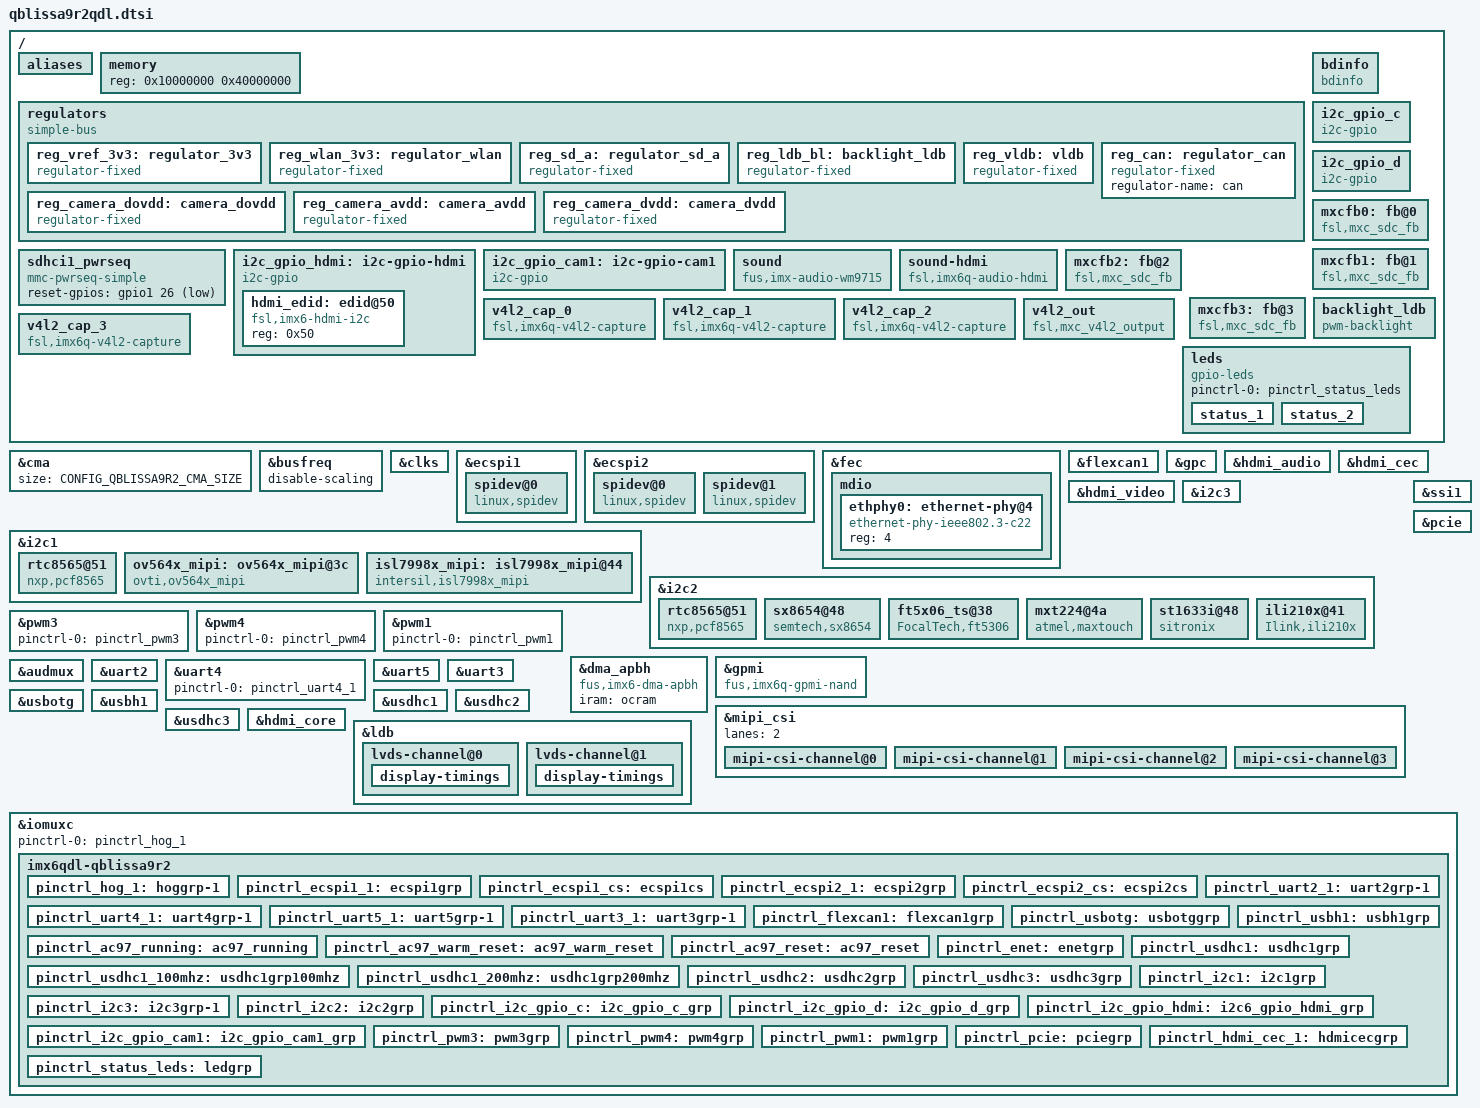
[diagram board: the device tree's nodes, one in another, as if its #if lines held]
/*
 * Copyright 2016-2017 F&S Elektronik Systeme GmbH
 *
 * This program is free software; you can redistribute it and/or modify
 * it under the terms of the GNU General Public License version 2 as
 * published by the Free Software Foundation.
 */

#include <dt-bindings/pwm/pwm.h>

/* Do we have HDMI? */
#if ((CONFIG_QBLISSA9R2_MXCFB0 == DISPLAY_HDMI) \
    || (CONFIG_QBLISSA9R2_MXCFB1 == DISPLAY_HDMI) \
    || (CONFIG_QBLISSA9R2_MXCFB2 == DISPLAY_HDMI) \
    || (CONFIG_QBLISSA9R2_MXCFB3 == DISPLAY_HDMI))
#define CONFIG_QBLISSA9R2_HDMI
#define CONFIG_QBLISSA9R2_HDMI_AUDIO
#define CONFIG_QBLISSA9R2_HDMI_CEC
#if ((CONFIG_QBLISSA9R2_MXCFB0 == DISPLAY_HDMI) \
    || (CONFIG_QBLISSA9R2_MXCFB1 == DISPLAY_HDMI))
#define __HDMI_ON_0_OR_1__	1
#define __HDMI_ON_2_OR_3__	0
#else
#define __HDMI_ON_0_OR_1__	0
#define __HDMI_ON_2_OR_3__	1
#endif
#endif

/* Do we have LVDS0? */
#if ((CONFIG_QBLISSA9R2_MXCFB0 == DISPLAY_LVDS0) \
    || (CONFIG_QBLISSA9R2_MXCFB1 == DISPLAY_LVDS0) \
    || (CONFIG_QBLISSA9R2_MXCFB2 == DISPLAY_LVDS0) \
    || (CONFIG_QBLISSA9R2_MXCFB3 == DISPLAY_LVDS0))
#define CONFIG_QBLISSA9R2_LVDS0
#if ((CONFIG_QBLISSA9R2_MXCFB0 == DISPLAY_LVDS0) \
    || (CONFIG_QBLISSA9R2_MXCFB1 == DISPLAY_LVDS0))
#define __LVDS0_ON_0_OR_1__	1
#define __LVDS0_ON_2_OR_3__	0
#else
#define __LVDS0_ON_0_OR_1__	0
#define __LVDS0_ON_2_OR_3__	1
#endif
#endif

/* Do we have LVDS1? */
#if ((CONFIG_QBLISSA9R2_MXCFB0 == DISPLAY_LVDS1) \
    || (CONFIG_QBLISSA9R2_MXCFB1 == DISPLAY_LVDS1) \
    || (CONFIG_QBLISSA9R2_MXCFB2 == DISPLAY_LVDS1) \
    || (CONFIG_QBLISSA9R2_MXCFB3 == DISPLAY_LVDS1))
#define CONFIG_QBLISSA9R2_LVDS1
#if ((CONFIG_QBLISSA9R2_MXCFB0 == DISPLAY_LVDS1) \
    || (CONFIG_QBLISSA9R2_MXCFB1 == DISPLAY_LVDS1))
#define __LVDS1_ON_0_OR_1__	1
#define __LVDS1_ON_2_OR_3__	0
#else
#define __LVDS1_ON_0_OR_1__	0
#define __LVDS1_ON_2_OR_3__	1
#endif
#endif

/* Check which LVDS will be the primary display */
#if (CONFIG_QBLISSA9R2_MXCFB0 == DISPLAY_LVDS0)
#define __LVDS0_PRIMARY__
#elif (CONFIG_QBLISSA9R2_MXCFB0 == DISPLAY_LVDS1)
#define __LVDS1_PRIMARY__
#elif (CONFIG_QBLISSA9R2_MXCFB1 == DISPLAY_LVDS0)
#define __LVDS0_PRIMARY__
#elif (CONFIG_QBLISSA9R2_MXCFB1 == DISPLAY_LVDS1)
#define __LVDS1_PRIMARY__
#elif (CONFIG_QBLISSA9R2_MXCFB2 == DISPLAY_LVDS0)
#define __LVDS0_PRIMARY__
#elif (CONFIG_QBLISSA9R2_MXCFB2 == DISPLAY_LVDS1)
#define __LVDS1_PRIMARY__
#elif (CONFIG_QBLISSA9R2_MXCFB3 == DISPLAY_LVDS0)
#define __LVDS0_PRIMARY__
#elif (CONFIG_QBLISSA9R2_MXCFB3 == DISPLAY_LVDS1)
#define __LVDS1_PRIMARY__
#endif

/* Check for invalid CONFIG combinations */

/* If SD_A is not active, also CD and WP may not be used */
#ifndef CONFIG_QBLISSA9R2_SD_A
#undef CONFIG_QBLISSA9R2_SD_A_CD
#undef CONFIG_QBLISSA9R2_SD_A_WP
#endif

/ {
	aliases {
		mxcfb0 = &mxcfb0;
		mxcfb1 = &mxcfb1;
		mxcfb2 = &mxcfb2;
		mxcfb3 = &mxcfb3;
#ifdef CONFIG_QBLISSA9R2_I2C_C
		i2c3 = &i2c_gpio_c;
#endif
#ifdef CONFIG_QBLISSA9R2_I2C_D
		i2c4 = &i2c_gpio_d;
#endif
#ifdef CONFIG_QBLISSA9R2_HDMI
		i2c5 = &i2c_gpio_hdmi;
#endif
#ifdef CONFIG_QBLISSA9R2_SERIAL_CAMERA
		i2c6 = &i2c_gpio_cam1;
#endif
	};

	memory {
		reg = <0x10000000 0x40000000>;
	};

	regulators {
		compatible = "simple-bus";

		reg_vref_3v3: regulator_3v3 {
			compatible = "regulator-fixed";
			regulator-name = "vref-3V3";
			regulator-min-microvolt = <3300000>;
			regulator-max-microvolt = <3300000>;
			regulator-always-on;
		};

#ifdef CONFIG_QBLISSA9R2_WLAN
		reg_wlan_3v3: regulator_wlan {
			compatible = "regulator-fixed";
			regulator-name = "vmmc-wlan-3v3";
			regulator-min-microvolt = <3300000>;
			regulator-max-microvolt = <3300000>;
//###			gpio = <&gpio1 26 GPIO_ACTIVE_HIGH>;
//###			enable-active-high;
			regulator-always-on;
		};
#endif

#ifdef CONFIG_QBLISSA9R2_SD_A
		reg_sd_a: regulator_sd_a {
			compatible = "regulator-fixed";
			regulator-name = "SD_A";
			regulator-min-microvolt = <3300000>;
			regulator-max-microvolt = <3300000>;
			gpio = <&gpio3 14 0>;
		};
#endif

		/* USB_OTG_PWR handled by USB controller, no regulator needed */
#if 0 //###
		reg_usb_otg_vbus: usb_otg_vbus {
			compatible = "regulator-fixed";
			regulator-name = "usb_otg_vbus";
			regulator-min-microvolt = <5000000>;
			regulator-max-microvolt = <5000000>;
			gpio = <&gpio3 22 GPIO_ACTIVE_LOW>;
		};
#endif //###

		/* USB_H1_PWR is always on, no regulator needed */
#if 0 //###
		reg_usb_h1_vbus: usb_h1_vbus {
			compatible = "regulator-fixed";
			regulator-name = "usb_h1_vbus";
			regulator-min-microvolt = <5000000>;
			regulator-max-microvolt = <5000000>;
			/* No way to switch USB1_H1_VBUS power */
			regulator-always-on;
		};
#endif //###

		/* LVDS backlight */
		reg_ldb_bl: backlight_ldb {
			compatible = "regulator-fixed";
			regulator-name = "ldb-bl";
			gpio = <&gpio2 8 GPIO_ACTIVE_HIGH>;
			regulator-min-microvolt = <3300000>;
			regulator-max-microvolt = <3300000>;
			enable-active-high;
		};

		/* LVDS logic supply power */
		reg_vldb: vldb {
			compatible = "regulator-fixed";
			regulator-name = "VLDB";
			gpio = <&gpio2 11 GPIO_ACTIVE_HIGH>;
			regulator-min-microvolt = <3300000>;
			regulator-max-microvolt = <3300000>;
			enable-active-high;
		};

		/* CAN */
		reg_can: regulator_can {
			compatible = "regulator-fixed";
			regulator-name = "can";
		};

#ifdef CONFIG_QBLISSA9R2_SERIAL_CAMERA
		reg_camera_dovdd: camera_dovdd {
			compatible = "regulator-fixed";
			regulator-name = "DOVDD-supply";
			regulator-min-microvolt = <1800000>;
			regulator-max-microvolt = <1800000>;
		};

		reg_camera_avdd: camera_avdd {
			compatible = "regulator-fixed";
			regulator-name = "VAVDD-supply";
			regulator-min-microvolt = <2800000>;
			regulator-max-microvolt = <2800000>;
		};

		reg_camera_dvdd: camera_dvdd {
			compatible = "regulator-fixed";
			regulator-name = "DVDD-supply";
			regulator-min-microvolt = <1500000>;
			regulator-max-microvolt = <1500000>;
		};
#endif /* CONFIG_QBLISSA9R2_SERIAL_CAMERA */
	};

	/* F&S board information */
	bdinfo: bdinfo {
		compatible = "bdinfo";
		board_name = "qblissa9r2";
		ecc_strength = "8";
	};

#if 1 //###
	sdhci1_pwrseq: sdhci1_pwrseq {
		compatible = "mmc-pwrseq-simple";
		reset-gpios = <&gpio1 26 GPIO_ACTIVE_LOW>;
	};
#endif //###

#ifdef CONFIG_QBLISSA9R2_I2C_C
	i2c_gpio_c: i2c_gpio_c {
		compatible = "i2c-gpio";
		gpios = <&gpio2 15 GPIO_ACTIVE_HIGH /* sda */
			 &gpio2 14 GPIO_ACTIVE_HIGH /* scl */
			>;
		pinctrl-names = "default";
		pinctrl-0 = <&pinctrl_i2c_gpio_c>;
//		i2c-gpio,sda-open-drain;
//		i2c-gpio,scl-open-drain;
		i2c-gpio,delay-us = <2>;        /* ~100 kHz */
		#address-cells = <1>;
		#size-cells = <0>;
	};
#endif

#ifdef CONFIG_QBLISSA9R2_I2C_D
	i2c_gpio_d: i2c_gpio_d {
		compatible = "i2c-gpio";
		gpios = <&gpio5 8 GPIO_ACTIVE_HIGH /* sda */
			 &gpio5 9 GPIO_ACTIVE_HIGH /* scl */
			>;
		pinctrl-names = "default";
		pinctrl-0 = <&pinctrl_i2c_gpio_d>;
		i2c-gpio,delay-us = <2>;        /* ~100 kHz */
		#address-cells = <1>;
		#size-cells = <0>;
	};
#endif

#ifdef CONFIG_QBLISSA9R2_HDMI
	i2c_gpio_hdmi: i2c-gpio-hdmi {
		compatible = "i2c-gpio";
		gpios = <&gpio5 10 GPIO_ACTIVE_HIGH /* sda */
			 &gpio5 11 GPIO_ACTIVE_HIGH /* scl */
			>;
		pinctrl-names = "default";
		pinctrl-0 = <&pinctrl_i2c_gpio_hdmi>;
		//i2c-gpio,sda-open-drain;
		//i2c-gpio,scl-open-drain;
		i2c-gpio,delay-us = <2>;        /* ~100 kHz */
		#address-cells = <1>;
		#size-cells = <0>;
	};
#endif

#ifdef CONFIG_QBLISSA9R2_SERIAL_CAMERA
	i2c_gpio_cam1: i2c-gpio-cam1 {
		compatible = "i2c-gpio";
		gpios = <&gpio6 0 GPIO_ACTIVE_HIGH /* sda */
			 &gpio6 1 GPIO_ACTIVE_HIGH /* scl */
			>;
		pinctrl-names = "default";
		pinctrl-0 = <&pinctrl_i2c_gpio_cam1>;
		i2c-gpio,delay-us = <2>;        /* ~100 kHz */
		#address-cells = <1>;
		#size-cells = <0>;
	};
#endif

#ifdef CONFIG_QBLISSA9R2_WM9715_AUDIO
	sound {
		compatible = "fus,imx-audio-wm9715";
		fus,model = "F&S Audio WM9715";
		audio-cpu = <&ssi1>;
		clocks = <&clks IMX6QDL_CLK_DUMMY>;
		mux-int-port = <1>;  /* SSI1=1, SSI2=2, SSI3=7 */
		mux-ext-port = <4>;
	};
#endif

#ifdef CONFIG_QBLISSA9R2_HDMI_AUDIO
	sound-hdmi {
		compatible = "fsl,imx6q-audio-hdmi", "fsl,imx-audio-hdmi";
		model = "imx-audio-hdmi";
		hdmi-controller = <&hdmi_audio>;
	};
#endif

	mxcfb0: fb@0 {
		compatible = "fsl,mxc_sdc_fb";
		late_init = <0>;
#if (CONFIG_QBLISSA9R2_MXCFB0 == DISPLAY_HDMI)
		disp_dev = "hdmi";
		default_bpp = <CONFIG_QBLISSA9R2_HDMI_BPP>;
		interface_pix_fmt = CONFIG_QBLISSA9R2_HDMI_PIX_FMT;
		int_clk = <0>;
		mode_str = CONFIG_QBLISSA9R2_HDMI_MODE_STR;
#elif (CONFIG_QBLISSA9R2_MXCFB0 == DISPLAY_LVDS0)
		disp_dev = "ldb";
		default_bpp = <CONFIG_QBLISSA9R2_LVDS0_BPP>;
		interface_pix_fmt = CONFIG_QBLISSA9R2_LVDS0_PIX_FMT;
		int_clk = <1>;
#elif (CONFIG_QBLISSA9R2_MXCFB0 == DISPLAY_LVDS1)
		disp_dev = "ldb";
		default_bpp = <CONFIG_QBLISSA9R2_LVDS1_BPP>;
		interface_pix_fmt = CONFIG_QBLISSA9R2_LVDS1_PIX_FMT;
		int_clk = <1>;
#else
		status = "disabled";
#endif
	};

	mxcfb1: fb@1 {
		compatible = "fsl,mxc_sdc_fb";
		late_init = <0>;
#if (CONFIG_QBLISSA9R2_MXCFB1 == DISPLAY_HDMI)
		disp_dev = "hdmi";
		default_bpp = <CONFIG_QBLISSA9R2_HDMI_BPP>;
		interface_pix_fmt = CONFIG_QBLISSA9R2_HDMI_PIX_FMT;
		int_clk = <0>;
		mode_str = CONFIG_QBLISSA9R2_HDMI_MODE_STR;
#elif (CONFIG_QBLISSA9R2_MXCFB1 == DISPLAY_LVDS0)
		disp_dev = "ldb";
		default_bpp = <CONFIG_QBLISSA9R2_LVDS0_BPP>;
		interface_pix_fmt = CONFIG_QBLISSA9R2_LVDS0_PIX_FMT;
		int_clk = <1>;
#elif (CONFIG_QBLISSA9R2_MXCFB1 == DISPLAY_LVDS1)
		disp_dev = "ldb";
		default_bpp = <CONFIG_QBLISSA9R2_LVDS1_BPP>;
		interface_pix_fmt = CONFIG_QBLISSA9R2_LVDS1_PIX_FMT;
		int_clk = <1>;
#else
		status = "disabled";
#endif
	};

	mxcfb2: fb@2 {
		compatible = "fsl,mxc_sdc_fb";
		late_init = <0>;
#if (CONFIG_QBLISSA9R2_MXCFB2 == DISPLAY_HDMI)
		disp_dev = "hdmi";
		default_bpp = <CONFIG_QBLISSA9R2_HDMI_BPP>;
		interface_pix_fmt = CONFIG_QBLISSA9R2_HDMI_PIX_FMT;
		int_clk = <0>;
		mode_str = CONFIG_QBLISSA9R2_HDMI_MODE_STR;
#elif (CONFIG_QBLISSA9R2_MXCFB2 == DISPLAY_LVDS0)
		disp_dev = "ldb";
		default_bpp = <CONFIG_QBLISSA9R2_LVDS0_BPP>;
		interface_pix_fmt = CONFIG_QBLISSA9R2_LVDS0_PIX_FMT;
		int_clk = <1>;
#elif (CONFIG_QBLISSA9R2_MXCFB2 == DISPLAY_LVDS1)
		disp_dev = "ldb";
		default_bpp = <CONFIG_QBLISSA9R2_LVDS1_BPP>;
		interface_pix_fmt = CONFIG_QBLISSA9R2_LVDS1_PIX_FMT;
		int_clk = <1>;
#else
		status = "disabled";
#endif
	};

	mxcfb3: fb@3 {
		compatible = "fsl,mxc_sdc_fb";
		late_init = <0>;
#if (CONFIG_QBLISSA9R2_MXCFB3 == DISPLAY_HDMI)
		disp_dev = "hdmi";
		default_bpp = <CONFIG_QBLISSA9R2_HDMI_BPP>;
		interface_pix_fmt = CONFIG_QBLISSA9R2_HDMI_PIX_FMT;
		int_clk = <0>;
		mode_str = CONFIG_QBLISSA9R2_HDMI_MODE_STR;
#elif (CONFIG_QBLISSA9R2_MXCFB3 == DISPLAY_LVDS0)
		disp_dev = "ldb";
		default_bpp = <CONFIG_QBLISSA9R2_LVDS0_BPP>;
		interface_pix_fmt = CONFIG_QBLISSA9R2_LVDS0_PIX_FMT;
		int_clk = <1>;
#elif (CONFIG_QBLISSA9R2_MXCFB3 == DISPLAY_LVDS1)
		disp_dev = "ldb";
		default_bpp = <CONFIG_QBLISSA9R2_LVDS1_BPP>;
		interface_pix_fmt = CONFIG_QBLISSA9R2_LVDS1_PIX_FMT;
		int_clk = <1>;
#else
		status = "disabled";
#endif
	};

#if (defined(CONFIG_QBLISSA9R2_LVDS0) || defined(CONFIG_QBLISSA9R2_LVDS1))
	/* LVDS backlight PWM (PWM3) */
	backlight_ldb {
		compatible = "pwm-backlight";
		pwms = <&pwm3 0 5000000>;
		power-supply = <&reg_ldb_bl>;
		brightness-levels = <0 1 5 10 18 28 41 56
				     73 92 113 137 163 192 222 255>;
		default-brightness-level = <14>;
		fb-names = "mxs-lcdif1";
	};
#endif

	/* Serial MIPI camera interface */
#ifdef CONFIG_QBLISSA9R2_SERIAL_CAMERA
	/* First capture device for first MIPI channel */
	v4l2_cap_0 {
		compatible = "fsl,imx6q-v4l2-capture";
		ipu_id = <0>;
		csi_id = <0>;
		mclk_source = <0>;
		status = "okay";
	};

	/* Second capture device, for second MIPI channel */
	v4l2_cap_1 {
		compatible = "fsl,imx6q-v4l2-capture";
		ipu_id = <0>;
		csi_id = <1>;
		mclk_source = <0>;
		status = "okay";
	};

#ifndef CONFIG_QBLISSA9R2_USE_ONE_IPU
	/* Third capture device, for third MIPI channel */
	v4l2_cap_2 {
		compatible = "fsl,imx6q-v4l2-capture";
		ipu_id = <1>;
		csi_id = <0>;
		mclk_source = <0>;
		status = "okay";
	};

	/* Fourth capture device, for fourth MIPI channel */
	v4l2_cap_3 {
		compatible = "fsl,imx6q-v4l2-capture";
		ipu_id = <1>;
		csi_id = <1>;
		mclk_source = <0>;
		status = "okay";
	};
#endif

	v4l2_out {
		compatible = "fsl,mxc_v4l2_output";
		status = "okay";
	};
#endif

	leds {
		compatible = "gpio-leds";
		pinctrl-names = "default";
		pinctrl-0 = <&pinctrl_status_leds>;

		status_1 {
			label = "Status1";
			gpios = <&gpio7 13 GPIO_ACTIVE_HIGH>;
			default-state = "keep";
		};

		status_2 {
			label = "Status2";
			gpios = <&gpio7 12 GPIO_ACTIVE_HIGH>;
			default-state = "keep";
		};
	};
};

/* RAM size for Continuous Memory Allocator; if not defined, use 320 MB */
#ifndef CONFIG_QBLISSA9R2_CMA_SIZE
#define CONFIG_QBLISSA9R2_CMA_SIZE 0x14000000
#endif
&cma {
	size = <CONFIG_QBLISSA9R2_CMA_SIZE>;
};

&busfreq {
	/* Disable bus frequency scaling, because reducing bus frequency to
	   24 MHz does not work with all types of DDR3 RAM */
	disable-scaling;
};

&clks {
	assigned-clocks = <&clks IMX6QDL_CLK_PLL4_AUDIO_DIV>,
			  <&clks IMX6QDL_CLK_SSI1_SEL>,
			  <&clks IMX6QDL_CLK_SSI1>;
	assigned-clock-parents = <0>,
				 <&clks IMX6QDL_CLK_PLL4_AUDIO_DIV>;
	/*
	 * The Audio-PLL (PLL4) must have at least 650MHz. The PLL post divider
	 * can divide by 1, 2 and 4, which means the lowest possible frequency
	 * is 162.5 MHz. Use 196.608 MHz, which is a multiple of 24.576 MHz.
	 * This is in turn a multiple of the commonly used audio bit rates.
	 */
	assigned-clock-rates = <196608000>, <196608000>, <24576000>;
};

#ifdef CONFIG_QBLISSA9R2_SPI_FLASH
&ecspi1 {
	fsl,spi-num-chipselects = <1>;
	cs-gpios = <&gpio2 30 GPIO_ACTIVE_HIGH>;
	pinctrl-names = "default";
	pinctrl-0 = <&pinctrl_ecspi1_1 &pinctrl_ecspi1_cs>;
	status = "okay";

	spidev@0 {
		#address-cells = <1>;
		#size-cells = <1>;
		compatible = "linux,spidev";
		spi-max-frequency = <20000000>;
		reg = <0>;
	};
};
#endif /* CONFIG_QBLISSA9R2_SPI_FLASH */

#ifdef CONFIG_QBLISSA9R2_SPI_A
/* SPI_A (2x CS) */
&ecspi2 {
	fsl,spi-num-chipselects = <2>;
	cs-gpios = <&gpio2 26 0>, <&gpio2 27 0>;
	pinctrl-names = "default";
	pinctrl-0 = <&pinctrl_ecspi2_1 &pinctrl_ecspi2_cs>;
	status = "okay";

	spidev@0 {
		#address-cells = <1>;
		#size-cells = <1>;
		compatible = "linux,spidev";
		spi-max-frequency = <20000000>;
		reg = <0>;
	};

	spidev@1 {
		#address-cells = <1>;
		#size-cells = <1>;
		compatible = "linux,spidev";
		spi-max-frequency = <20000000>;
		reg = <1>;
	};
};
#endif /* CONFIG_QBLISSA9R2_SPI_A */

&fec {
	pinctrl-names = "default";
	pinctrl-0 = <&pinctrl_enet>;
	phy-mode = "rgmii-id";
	phy-handle = <&ethphy0>;
	phy-supply = <&reg_vref_3v3>;
	status = "okay";

	mdio {
		#address-cells = <1>;
		#size-cells = <0>;

		ethphy0: ethernet-phy@4 {
			compatible = "ethernet-phy-ieee802.3-c22";
			reg = <4>;
			/* Set the maximum link speed if required */
			//max-speed = <100>;
		};
	};
};

/* CAN_A implemented by FLEXCAN1 */
&flexcan1 {
	pinctrl-names = "default";
	pinctrl-0 = <&pinctrl_flexcan1>;
	xceiver-supply = <&reg_can>;
	status = "okay";
};

&gpc {
	fsl,cpu_pupscr_sw2iso = <0xf>;
	fsl,cpu_pupscr_sw = <0xf>;
	fsl,cpu_pdnscr_iso2sw = <0x1>;
	fsl,cpu_pdnscr_iso = <0x1>;
	fsl,ldo-bypass = <0>; /* use ldo-bypass, u-boot will check it and configure */
	fsl,wdog-reset = <1>; /* watchdog select of reset source */
};

#ifdef CONFIG_QBLISSA9R2_HDMI_AUDIO
&hdmi_audio {
	status = "okay";
};
#endif

#ifdef CONFIG_QBLISSA9R2_HDMI_CEC
&hdmi_cec {
//###	pinctrl-names = "default";
//###	pinctrl-0 = <&pinctrl_hdmi_cec_1>;
	status = "okay";
};
#endif

#ifdef CONFIG_QBLISSA9R2_HDMI
&hdmi_video {
	fsl,phy_reg_vlev = <0x0294>;
	fsl,phy_reg_cksymtx = <0x800d>;
	hpd-active-low;
	force-dvi-mode;
	status = "okay";
};
#endif

/* I2C1 is used internally (RTC, EEPROM) and for cameras, always active */
&i2c1{
	clock-frequency = <100000>;
	pinctrl-names = "default";
	pinctrl-0 = <&pinctrl_i2c1>;
	status = "okay";

#if (CONFIG_QBLISSA9R2_BOARD_REVISION < 110)
	rtc8565@51 {
		compatible = "nxp,pcf8565", "nxp,pcf8563";
		reg = <0x51>;
		interrupt-parent = <&gpio1>;
		interrupts = <28 IRQ_TYPE_EDGE_FALLING>;
	};
#endif

#ifdef CONFIG_QBLISSA9R2_SERIAL_CAMERA
#ifdef CONFIG_QBLISSA9R2_MIPI_CAMERA_OV564X
	ov564x_mipi: ov564x_mipi@3c {
		compatible = "ovti,ov564x_mipi";
		reg = <0x3c>;
		clocks = <&clks 201>;
		clock-names = "csi_mclk";
		DOVDD-supply = <&reg_camera_dovdd>;
		AVDD-supply = <&reg_camera_avdd>;
		DVDD-supply = <&reg_camera_dvdd>;
		en-gpios = <&gpio5 24 GPIO_ACTIVE_LOW>;
		rst-gpios = <&gpio5 23 GPIO_ACTIVE_LOW>;
		csi_id = <0>;
		mclk = <24000000>;
		mclk_source = <0>;
	};
#endif
#ifdef CONFIG_QBLISSA9R2_MIPI_CAMERA_ISL7998X
	isl7998x_mipi: isl7998x_mipi@44 {
		compatible = "intersil,isl7998x_mipi";
		reg = <0x44>;
		clocks = <&clks IMX6QDL_CLK_CKO2>;
		clock-names = "csi_mclk";
		mclk = <27000000>;
	};
#endif
#endif
};

#ifdef CONFIG_QBLISSA9R2_I2C_A
/* I2C_A is implemented via I2C3 */
&i2c3 {
	clock-frequency = <100000>;
	pinctrl-names = "default";
	pinctrl-0 = <&pinctrl_i2c3>;
	status = "okay";

	/* Add devices here */
};
#endif /* CONFIG_QBLISSA9R2_I2C_A */

#ifdef CONFIG_QBLISSA9R2_I2C_B
/* I2C_B is implemented via I2C2 (SMB, with IRQ, used for touches) */
&i2c2 {
	clock-frequency = <100000>;
	pinctrl-names = "default";
	pinctrl-0 = <&pinctrl_i2c2>;
	status = "okay";

#if (CONFIG_QBLISSA9R2_BOARD_REVISION >= 110)
	rtc8565@51 {
		compatible = "nxp,pcf8565", "nxp,pcf8563";
		reg = <0x51>;
		interrupt-parent = <&gpio1>;
		interrupts = <28 IRQ_TYPE_EDGE_FALLING>;
	};
#endif

#ifdef CONFIG_QBLISSA9R2_4WTOUCH_SX8655
	/* 4/5 wire analog resistive touch */
	sx8654@48 {
		compatible = "semtech,sx8654";
		reg = <0x48>;
		touchrate = <0x30>;
		powdly = <0x06>;
		filt = <0x02>;
		setdly = <0x08>;
		pinctrl-names = "default";
		interrupt-parent = <&gpio1>;
		interrupts = <30 IRQ_TYPE_EDGE_FALLING>;
		reset-gpio = <&gpio6 14 GPIO_ACTIVE_LOW>;
	};
#endif

#ifdef CONFIG_QBLISSA9R2_CAPTOUCH_FT5x06
	/* F&S driver V3.0 */
	ft5x06_ts@38 {
		compatible = "FocalTech,ft5306";
		reg = <0x38>;
		fingers = <2>;
		touchscreen-size-x = <800>;
		touchscreen-size-y = <480>;
		threshold = <25>;
		interrupt-parent = <&gpio1>;
		interrupts = <30 IRQ_TYPE_EDGE_FALLING>;
		reset-gpio = <&gpio6 14 GPIO_ACTIVE_LOW>;
		linux,wakeup;
	};
#endif

#ifdef CONFIG_QBLISSA9R2_CAPTOUCH_MXT224
	/* Atmel PCAP touch */
	mxt224@4a {
		compatible = "atmel,maxtouch";
		reg = <0x4a>;
		interrupt-parent = <&gpio1>;
		interrupts = <30 IRQ_TYPE_EDGE_FALLING>;
		atmel,cfg_name = "atmel/mxt224.cfg";
		atmel,reset-gpio = <&gpio6 14 GPIO_ACTIVE_LOW>;
	};
#endif

#ifdef CONFIG_QBLISSA9R2_CAPTOUCH_SITRONIX
	/* Sitronix PCAP touch */
	st1633i@48 {
		compatible = "sitronix";
		reg = <0x48>;
		swap-xy;
		interrupt-parent = <&gpio1>;
		interrupts = <30 IRQ_TYPE_EDGE_FALLING>;
		reset-gpio = <&gpio6 14 GPIO_ACTIVE_LOW>;
	};
#endif

#ifdef CONFIG_QBLISSA9R2_CAPTOUCH_ILINK
	/* Ilink PCAP touch */
	ili210x@41 {
		compatible = "Ilink,ili210x";
		reg = <0x41>;
		interrupt-parent = <&gpio1>;
		interrupts = <30 IRQ_TYPE_EDGE_FALLING>;
		reset-gpio = <&gpio6 14 GPIO_ACTIVE_LOW>;
	};
#endif
};
#endif /* CONFIG_QBLISSA9R2_I2C_B */

#ifdef CONFIG_QBLISSA9R2_I2C_C
/* I2C_C (LVDS_DID) is a Soft-I2C */
&i2c_gpio_c {
	/* Add devices here */
};
#endif

#ifdef CONFIG_QBLISSA9R2_I2C_D
/* I2C_D (LVDS_BLC) is a Soft-I2C */
&i2c_gpio_d {
	/* Add devices here */
};
#endif

#ifdef CONFIG_QBLISSA9R2_HDMI
&i2c_gpio_hdmi {
	hdmi_edid: edid@50 {
		compatible = "fsl,imx6-hdmi-i2c";
		reg = <0x50>;
	};
};
#endif

#ifdef CONFIG_QBLISSA9R2_SERIAL_CAMERA
/* This is a hardware option for Camera1 if Camera0 has the same I2C address */
&i2c_gpio_cam1 {
	/* Add Camera1 device here */
};
#endif

#ifdef CONFIG_QBLISSA9R2_PWM_A
/* PWM_A/LVDS_BLT_CTRL, pin 123 */
&pwm3 {
	pinctrl-names = "default";
	pinctrl-0 = <&pinctrl_pwm3>;
	status = "okay";
};
#endif

#ifdef CONFIG_QBLISSA9R2_PWM_B
/* PWM_B/FAN_PWMOUT, pin 196 */
&pwm4 {
	pinctrl-names = "default";
	pinctrl-0 = <&pinctrl_pwm4>;
	status = "okay";
};
#endif

#ifdef CONFIG_QBLISSA9R2_PWM_C
/* PWM_C/SPKR, pin 194 */
&pwm1 {
	pinctrl-names = "default";
	pinctrl-0 = <&pinctrl_pwm1>;
	status = "okay";
};
#endif

&dma_apbh {
	/* Switch to F&S implementation of APBH DMA driver for GPMI (NAND) */
	compatible = "fus,imx6-dma-apbh", "fus,imx28-dma-apbh";
	iram = <&ocram>;
};

#ifdef CONFIG_QBLISSA9R2_NAND
&gpmi {
	/* Switch to F&S implementation of GPMI NAND driver */
	compatible = "fus,imx6q-gpmi-nand";
	pinctrl-names = "default";
//###	pinctrl-0 = <&pinctrl_gpmi_nand_1>;
	fus,skipblocks = <2>;
	fus,chunk1k;
	fus,ecc_strength = <8>;		/* Spare area 64 bytes */
	//fus,ecc_strength = <40>;	/* Spare area 224 bytes */
	status = "okay";
};
#endif

#ifdef CONFIG_QBLISSA9R2_SERIAL_CAMERA
&mipi_csi {
	status = "okay";
	lanes = <2>;

	mipi-csi-channel@0 {
		ipu_id = <0>;
		csi_id = <0>;
		v_channel = <0>;
		status = "okay";
	};

	mipi-csi-channel@1 {
		ipu_id = <0>;
		csi_id = <1>;
		v_channel = <1>;
		status = "okay";
	};

#ifndef CONFIG_QBLISSA9R2_USE_ONE_IPU
	mipi-csi-channel@2 {
		ipu_id = <1>;
		csi_id = <0>;
		v_channel = <2>;
		status = "okay";
	};

	mipi-csi-channel@3 {
		ipu_id = <1>;
		csi_id = <1>;
		v_channel = <3>;
		status = "okay";
	};
#endif
};
#endif

#ifdef CONFIG_QBLISSA9R2_WM9715_AUDIO
&audmux {
	status = "okay";
};

&ssi1 {
	fsl,mode = "ac97-slave";
	cell-index = <0>;
	pinctrl-names = "ac97-running", "ac97-reset", "ac97-warm-reset";
	pinctrl-0 = <&pinctrl_ac97_running>;
	pinctrl-1 = <&pinctrl_ac97_reset>;
	pinctrl-2 = <&pinctrl_ac97_warm_reset>;
	ac97-gpios = <&gpio5 16 0 &gpio5 15 0 &gpio5 12 0>;
	status = "okay";
};
#endif

#ifdef CONFIG_QBLISSA9R2_UART_A
/* UART_A is implemented via UART2 */
&uart2 {
	pinctrl-names = "default";
	pinctrl-0 = <&pinctrl_uart2_1>;
	fsl,uart-has-rtscts;
	status = "okay";
};
#endif /* CONFIG_QBLISSA9R2_UART_A */

#ifdef CONFIG_QBLISSA9R2_UART_B
/* UART_B is implemented via UART4 */
&uart4 {
	pinctrl-names = "default";
	pinctrl-0 = <&pinctrl_uart4_1>;
	status = "okay";
};
#endif /* CONFIG_QBLISSA9R2_UART_B */

#ifdef CONFIG_QBLISSA9R2_UART_C
/* UART_C is implemented via UART5 (debug port) */
&uart5 {
	pinctrl-names = "default";
	pinctrl-0 = <&pinctrl_uart5_1>;
	fsl,uart-has-rtscts;
	status = "okay";
};
#endif /* CONFIG_QBLISSA9R2_UART_C */

#if defined(CONFIG_QBLISSA9R2_UART_D) || defined(CONFIG_QBLISSA9R2_BLUETOOTH)
/* UART_Dis implemented via UART3; used for HCI if bluetooth is equipped */
&uart3 {
	pinctrl-names = "default";
	pinctrl-0 = <&pinctrl_uart3_1>;
	fsl,uart-has-rtscts;
	status = "okay";
};
#endif /* CONFIG_QBLISSA9R2_UART_D || CONFIG_QBLISSA9R2_BLUETOOTH */

&usbotg {
	pinctrl-names = "default";
	pinctrl-0 = <&pinctrl_usbotg>;
//###	vbus-supply = <&reg_usb_otg_vbus>;
#ifndef CONFIG_QBLISSA9R2_HAVE_USB_OTG_OC
	disable-over-current;
#endif
	status = "okay";
};

&usbh1 {
	pinctrl-names = "default";
	pinctrl-0 = <&pinctrl_usbh1>;
//###	vbus-supply = <&reg_usb_h1_vbus>;
	disable-over-current;
	status = "okay";
};

#ifdef CONFIG_QBLISSA9R2_WLAN
&usdhc1 {
	pinctrl-names = "default", "state_100mhz", "state_200mhz";
	pinctrl-0 = <&pinctrl_usdhc1>;
	pinctrl-1 = <&pinctrl_usdhc1_100mhz>;
	pinctrl-2 = <&pinctrl_usdhc1_200mhz>;
	/* WLAN is non-removable, but CD tells us if it is equipped or not */
	cd-gpios = <&gpio1 1 GPIO_ACTIVE_LOW>;
	//non-removable;
	bus-width = <4>;
	vmmc-supply = <&reg_wlan_3v3>;	/* VDD */
	vqmmc-supply = <&reg_vref_3v3>;	/* VDD_IO */
	voltage-ranges = <3300 3300>;
	no-1-8-v;
	keep-power-in-suspend;
	enable-sdio-wakeup;
	mmc-pwrseq = <&sdhci1_pwrseq>;
	status = "okay";
};
#endif

#ifdef CONFIG_QBLISSA9R2_SD_A
&usdhc2 {
	/* Micro-SD-Card-Slot, CD is active low */
	pinctrl-names = "default";
	pinctrl-0 = <&pinctrl_usdhc2>;
#ifdef CONFIG_QBLISSA9R2_SD_A_CD
	cd-gpios = <&gpio1 4 GPIO_ACTIVE_LOW>;
#else
	non-removable;
#endif
#ifdef CONFIG_QBLISSA9R2_SD_A_WP
	wp-gpios = <&gpio1 2 GPIO_ACTIVE_HIGH>;
#endif
	bus-width = <4>;
	vmmc-supply = <&reg_sd_a>;	/* VDD */
	vqmmc-supply = <&reg_vref_3v3>;	/* VDD_IO */
	voltage-ranges = <3300 3300>;
	no-1-8-v;
	keep-power-in-suspend;
	status = "okay";
};
#endif /* CONFIG_QBLISSA9R2_SD_A */

#ifdef CONFIG_QBLISSA9R2_EMMC
&usdhc3 {
	pinctrl-names = "default";
	pinctrl-0 = <&pinctrl_usdhc3>;
	non-removable;
	bus-width = <8>;
	vmmc-supply = <&reg_vref_3v3>;	/* VDD */
	vqmmc-supply = <&reg_vref_3v3>;	/* VDD_IO */
	voltage-ranges = <3300 3300>;
	no-1-8-v;
	keep-power-in-suspend;
	status = "okay";
};
#endif

#ifdef CONFIG_QBLISSA9R2_PCIE
&pcie {
	pinctrl-names = "default";
	pinctrl-0 = <&pinctrl_pcie>;
	power-on-gpio = <&gpio6 16 GPIO_ACTIVE_LOW>;
	reset-gpio = <&gpio6 14 GPIO_ACTIVE_LOW>;
	status = "okay";
};
#endif

#ifdef CONFIG_QBLISSA9R2_HDMI
&hdmi_core {
#ifdef CONFIG_QBLISSA9R2_USE_ONE_IPU
	/*
	 * When using one IPU (id=0):
	 * HDMI can go to DI1, unless LVDS1 is also active. In this case LVDS1
	 * must go to DI1 and HDMI to DI0.
	 */
	ipu_id = <0>;
#if (__HDMI_ON_0_OR_1__ && __LVDS1_ON_0_OR_1__)
	disp_id = <0>;
#else
	disp_id = <1>;
#endif
#else /* !CONFIG_QBLISSA9R2_USE_ONE_IPU */
	/*
	 * When using two IPUs:
	 * HDMI can always go to IPU2 (id=1), DI1.
	 */
	disp_id = <1>;
	ipu_id = <0>;
#endif /* CONFIG_QBLISSA9R2_USE_ONE_IPU */
	status = "okay";
};
#endif

#if (defined(CONFIG_QBLISSA9R2_LVDS0) || defined(CONFIG_QBLISSA9R2_LVDS1))
&ldb {
	ext_ref;
#if defined(CONFIG_QBLISSA9R2_LVDS_SPLIT_MODE)
	split-mode;
#elif defined(CONFIG_QBLISSA9R2_LVDS_DUAL_MODE)
	dual-mode;
#endif
	ldb-supply = <&reg_vldb>;
	status = "okay";

#ifdef CONFIG_QBLISSA9R2_LVDS0
	/* LVDS0 must always go to DI0 of an IPU! */
	lvds-channel@0 {
		reg = <0>;
#ifdef CONFIG_QBLISSA9R2_USE_ONE_IPU
		crtc = "ipu1-di0";
#else
		crtc = "ipu2-di0";
#endif
		fsl,data-mapping = CONFIG_QBLISSA9R2_LVDS0_MAPPING;
		fsl,data-width = <CONFIG_QBLISSA9R2_LVDS0_DATA_WIDTH>;
#ifdef __LVDS0_PRIMARY__
		primary;
#endif
		status = "okay";

		display-timings {
			native-mode = <&timing0>;
			timing0: CONFIG_QBLISSA9R2_LVDS0_TIMING;
		};
	};
#endif

#ifdef CONFIG_QBLISSA9R2_LVDS1
	/* LVDS1 must always go to DI1 of an IPU! */
	lvds-channel@1 {
#if defined(CONFIG_QBLISSA9R2_LVDS_DUAL_MODE) \
	|| defined(CONFIG_QBLISSA9R2_LVDS_SPLIT_MODE)
		reg = <0>;
#else
		reg = <1>;
#endif
#if (defined(CONFIG_QBLISSA9R2_USE_ONE_IPU) \
	|| (__LVDS0_ON_0_OR_1__ && __LVDS1_ON_0_OR_1__) \
	|| (__LVDS0_ON_2_OR_3__ && __LVDS1_ON_2_OR_3__))
		crtc = "ipu1-di1";
#else
		crtc = "ipu2-di1";
#endif
		fsl,data-mapping = CONFIG_QBLISSA9R2_LVDS1_MAPPING;
		fsl,data-width = <CONFIG_QBLISSA9R2_LVDS1_DATA_WIDTH>;
#ifdef __LVDS1_PRIMARY__
		primary;
#endif
		status = "okay";

		display-timings {
			native-mode = <&timing1>;
			timing1: CONFIG_QBLISSA9R2_LVDS1_TIMING;
		};
	};
#endif
};

#endif /* CONFIG_QBLISSA9R2_LVDS0 || CONFIG_QBLISSA9R2_LVDS1 */

&iomuxc {
	pinctrl-names = "default";
	pinctrl-0 = <&pinctrl_hog_1>;

	imx6qdl-qblissa9r2  {
		/* Pin configs that don't belong anywhere else */
		pinctrl_hog_1: hoggrp-1 {
			fsl,pins = <
				/* VLCD_ON */
				MX6QDL_PAD_SD4_DAT3__GPIO2_IO11		0x030b0

				/* VCFL_ON */
				MX6QDL_PAD_SD4_DAT0__GPIO2_IO08		0x030b0

				/* RTC_IRQ */
				MX6QDL_PAD_ENET_TX_EN__GPIO1_IO28	0x030b0
				/* SUSPEND S3*/
				MX6QDL_PAD_EIM_DA0__GPIO3_IO00		0x0b0b0
				/* SUSPEND S5*/
				MX6QDL_PAD_EIM_DA1__GPIO3_IO01		0x0b0b0
				/* SUSPEND STAT */
				MX6QDL_PAD_EIM_DA2__GPIO3_IO02		0x0b0b0
				/* POWER BTN */
				MX6QDL_PAD_EIM_DA3__GPIO3_IO03		0x0b0b0
				/* LID BTN */
				MX6QDL_PAD_EIM_DA4__GPIO3_IO04		0x0b0b0
				/* SLP_BTN */
				MX6QDL_PAD_EIM_DA5__GPIO3_IO05		0x0b0b0
				/* BATTERY LOW */
				MX6QDL_PAD_EIM_DA6__GPIO3_IO06		0x0b0b0
				/* THRM */
				MX6QDL_PAD_EIM_DA7__GPIO3_IO07		0x0b0b0
				/* THRMTRIP */
				MX6QDL_PAD_EIM_DA8__GPIO3_IO08		0x0b0b0
				/* WAKE */
				MX6QDL_PAD_EIM_DA9__GPIO3_IO09		0x0b0b0
				/* WATCHDOG OUT */
				MX6QDL_PAD_EIM_DA10__GPIO3_IO10		0x030b0
				/* WATCHDOG TRIGGER */
				MX6QDL_PAD_EIM_DA11__GPIO3_IO11		0x0b0b0
				/* FAN TACHOMETER INPUT */
				MX6QDL_PAD_EIM_DA12__GPIO3_IO12		0x0b0b0
				/* SATA ACT */
				MX6QDL_PAD_EIM_DA13__GPIO3_IO13		0x0b0b0

				/* PCIe-RST, also used as touch reset */
				MX6QDL_PAD_NANDF_CS1__GPIO6_IO14	0x030b0
			>;
		};

#if 0
		/* Pins already set in bootloader */
		pinctrl_gpmi_nand_1: gpmi-nand-1 {
			fsl,pins = <
				MX6QDL_PAD_NANDF_CLE__NAND_CLE		0x0b0b1
				MX6QDL_PAD_NANDF_ALE__NAND_ALE		0x0b0b1
				MX6QDL_PAD_NANDF_WP_B__NAND_WP_B	0x0b0b1
				MX6QDL_PAD_NANDF_RB0__NAND_READY_B	0x0b000
				MX6QDL_PAD_NANDF_CS0__NAND_CE0_B	0x0b0b1
				MX6QDL_PAD_SD4_CMD__NAND_RE_B		0x0b0b1
				MX6QDL_PAD_SD4_CLK__NAND_WE_B		0x0b0b1
				MX6QDL_PAD_NANDF_D0__NAND_DATA00	0x0b0b1
				MX6QDL_PAD_NANDF_D1__NAND_DATA01	0x0b0b1
				MX6QDL_PAD_NANDF_D2__NAND_DATA02	0x0b0b1
				MX6QDL_PAD_NANDF_D3__NAND_DATA03	0x0b0b1
				MX6QDL_PAD_NANDF_D4__NAND_DATA04	0x0b0b1
				MX6QDL_PAD_NANDF_D5__NAND_DATA05	0x0b0b1
				MX6QDL_PAD_NANDF_D6__NAND_DATA06	0x0b0b1
				MX6QDL_PAD_NANDF_D7__NAND_DATA07	0x0b0b1
			>;
		};
#endif

#ifdef CONFIG_QBLISSA9R2_SPI_FLASH
		/* ECSPI1 - SPI flash */
		pinctrl_ecspi1_1: ecspi1grp {
			fsl,pins = <
				MX6QDL_PAD_EIM_D17__ECSPI1_MISO		0x100b1
				MX6QDL_PAD_EIM_D18__ECSPI1_MOSI		0x100b1
				MX6QDL_PAD_EIM_D16__ECSPI1_SCLK		0x100b1
			>;
		};

		pinctrl_ecspi1_cs: ecspi1cs {
			fsl,pins = <
				/* ECSPI1_SS0 - slave (chip) select 0 */
				MX6QDL_PAD_EIM_EB2__GPIO2_IO30		0x1b0b0
			>;
		};
#endif /* CONFIG_QBLISSA9R2_SPI_FLASH */

#ifdef CONFIG_QBLISSA9R2_SPI_A
		/* ECSPI2 - SPI_A */
		pinctrl_ecspi2_1: ecspi2grp {
			fsl,pins = <
				MX6QDL_PAD_EIM_OE__ECSPI2_MISO		0x100b1
				MX6QDL_PAD_EIM_CS1__ECSPI2_MOSI		0x100b1
				MX6QDL_PAD_EIM_CS0__ECSPI2_SCLK		0x100b1
			>;
		};

		pinctrl_ecspi2_cs: ecspi2cs {
			fsl,pins = <
				/* ECSPI2_SS0 - slave (chip) select 0 */
				MX6QDL_PAD_EIM_RW__GPIO2_IO26		0x1b0b0
				/* ECSPI2_SS1  - slave (chip) select 1 */
				MX6QDL_PAD_EIM_LBA__GPIO2_IO27		0x1b0b0
			>;
		};
#endif

#ifdef CONFIG_QBLISSA9R2_UART_A
		/* UART2 on pins 171/172/177/178 */
		pinctrl_uart2_1: uart2grp-1{
			fsl,pins = <
				MX6QDL_PAD_EIM_D26__UART2_TX_DATA	0x1b0b1
				MX6QDL_PAD_EIM_D27__UART2_RX_DATA	0x1b0b1
				MX6QDL_PAD_EIM_D28__UART2_CTS_B		0x1b0b1
				MX6QDL_PAD_EIM_D29__UART2_RTS_B		0x1b0b1
			>;
		};
#endif

#ifdef CONFIG_QBLISSA9R2_UART_B
		/* UART4 on pins 208/209 */
		pinctrl_uart4_1: uart4grp-1{
			fsl,pins = <
				MX6QDL_PAD_KEY_COL0__UART4_TX_DATA	0x1b0b1
				MX6QDL_PAD_KEY_ROW0__UART4_RX_DATA	0x1b0b1
			>;
		};
#endif

#ifdef CONFIG_QBLISSA9R2_UART_C
		/* UART5 on pins 185-188 (debug port) */
		pinctrl_uart5_1: uart5grp-1{
			fsl,pins = <
				MX6QDL_PAD_KEY_COL1__UART5_TX_DATA	0x1b0b1
				MX6QDL_PAD_KEY_ROW1__UART5_RX_DATA	0x1b0b1
				MX6QDL_PAD_KEY_ROW4__UART5_CTS_B	0x1b0b1
				MX6QDL_PAD_KEY_COL4__UART5_RTS_B	0x1b0b1
			>;
		};
#endif

#if defined(CONFIG_QBLISSA9R2_UART_D) || defined(CONFIG_QBLISSA9R2_BLUETOOTH)
		/* UART3 either on WLAN/BT or pins 161-164 */
		pinctrl_uart3_1: uart3grp-1{
			fsl,pins = <
				MX6QDL_PAD_EIM_D24__UART3_TX_DATA	0x1b0b1
				MX6QDL_PAD_EIM_D25__UART3_RX_DATA	0x1b0b1
				MX6QDL_PAD_EIM_D30__UART3_CTS_B		0x1b0b1
				MX6QDL_PAD_EIM_D31__UART3_RTS_B		0x1b0b1
			>;
		};
#endif

		pinctrl_flexcan1: flexcan1grp {
			fsl,pins = <
				MX6QDL_PAD_KEY_COL2__FLEXCAN1_TX	0x1b020
				MX6QDL_PAD_KEY_ROW2__FLEXCAN1_RX	0x1b020
			>;
		};

		pinctrl_usbotg: usbotggrp {
			fsl,pins = <
				/* USB_OTG_PWR, active low */
//###				MX6QDL_PAD_EIM_D22__GPIO3_IO22		0x0b030
				MX6QDL_PAD_EIM_D22__USB_OTG_PWR		0x0b030
#ifdef CONFIG_QBLISSA9R2_HAVE_USB_OTG_OC
				/* USB_OTG_OC (part of USB_OC01), active low */
				MX6QDL_PAD_EIM_D21__USB_OTG_OC		0x1b000
#endif
				/* USB_OTG_ID: low: host, open: device */
				MX6QDL_PAD_ENET_RX_ER__USB_OTG_ID	0x1b000
			>;
		};

		pinctrl_usbh1: usbh1grp {
			fsl,pins = <
				/* USB hub reset line, active low */
				MX6QDL_PAD_EIM_DA15__GPIO3_IO15		0x0b0b0
				/* USB H1 host power is always on */
			>;
		};

#ifdef CONFIG_QBLISSA9R2_WM9715_AUDIO
		pinctrl_ac97_running: ac97_running {
			fsl,pins = <
				MX6QDL_PAD_DISP0_DAT21__AUD4_TXD	0x170b9
				MX6QDL_PAD_DISP0_DAT22__AUD4_TXFS	0x170b9
				MX6QDL_PAD_DISP0_DAT23__AUD4_RXD	0x120f9
				MX6QDL_PAD_DISP0_DAT20__AUD4_TXC	0x120f9
				MX6QDL_PAD_DISP0_DAT18__GPIO5_IO12	0x1b0b0
			>;
		};

		pinctrl_ac97_warm_reset: ac97_warm_reset {
			fsl,pins = <
				MX6QDL_PAD_DISP0_DAT21__AUD4_TXD	0x170b9
				MX6QDL_PAD_DISP0_DAT22__GPIO5_IO16	0x170b9
				MX6QDL_PAD_DISP0_DAT23__AUD4_RXD	0x120f9
				MX6QDL_PAD_DISP0_DAT20__AUD4_TXC	0x120f9
				MX6QDL_PAD_DISP0_DAT18__GPIO5_IO12	0x1b0b0
			>;
		};

		pinctrl_ac97_reset: ac97_reset {
			fsl,pins = <
				MX6QDL_PAD_DISP0_DAT21__GPIO5_IO15	0x170b9
				MX6QDL_PAD_DISP0_DAT22__GPIO5_IO16	0x170b9
				MX6QDL_PAD_DISP0_DAT23__AUD4_RXD	0x120f9
				MX6QDL_PAD_DISP0_DAT20__AUD4_TXC	0x120f9
				MX6QDL_PAD_DISP0_DAT18__GPIO5_IO12	0x1b0b0
			>;
		};
#endif

		pinctrl_enet: enetgrp {
			fsl,pins = <
				MX6QDL_PAD_ENET_MDIO__ENET_MDIO		0x1b0b0
				MX6QDL_PAD_ENET_MDC__ENET_MDC		0x1b0b0
				MX6QDL_PAD_RGMII_TXC__RGMII_TXC		0x1b0b0
				MX6QDL_PAD_RGMII_TD0__RGMII_TD0		0x1b0b0
				MX6QDL_PAD_RGMII_TD1__RGMII_TD1		0x1b0b0
				MX6QDL_PAD_RGMII_TD2__RGMII_TD2		0x1b0b0
				MX6QDL_PAD_RGMII_TD3__RGMII_TD3		0x1b0b0
				MX6QDL_PAD_RGMII_TX_CTL__RGMII_TX_CTL	0x1b0b0
				MX6QDL_PAD_ENET_REF_CLK__ENET_TX_CLK	0x1b0b0
				MX6QDL_PAD_RGMII_RXC__RGMII_RXC		0x1b0b0
				MX6QDL_PAD_RGMII_RD0__RGMII_RD0		0x1b0b0
				MX6QDL_PAD_RGMII_RD1__RGMII_RD1		0x1b0b0
				MX6QDL_PAD_RGMII_RD2__RGMII_RD2		0x1b0b0
				MX6QDL_PAD_RGMII_RD3__RGMII_RD3		0x1b0b0
				MX6QDL_PAD_RGMII_RX_CTL__RGMII_RX_CTL	0x1b0b0
				/* Phy interrupt IO pin*/
				MX6QDL_PAD_GPIO_19__GPIO4_IO05		0x4001b0a8
				/* Phy reset IO pin*/
				MX6QDL_PAD_ENET_CRS_DV__GPIO1_IO25	0x4001b0a8
			>;
		};

#ifdef CONFIG_QBLISSA9R2_WLAN
		pinctrl_usdhc1:usdhc1grp {
			fsl,pins = <
				MX6QDL_PAD_SD1_CMD__SD1_CMD		0x17091
				MX6QDL_PAD_SD1_CLK__SD1_CLK		0x10091
				MX6QDL_PAD_SD1_DAT0__SD1_DATA0		0x17091
				MX6QDL_PAD_SD1_DAT1__SD1_DATA1		0x17091
				MX6QDL_PAD_SD1_DAT2__SD1_DATA2		0x17091
				MX6QDL_PAD_SD1_DAT3__SD1_DATA3		0x17091
				/* WLAN_RESET with external pull-down */
				MX6QDL_PAD_ENET_RXD1__GPIO1_IO26	0x10090
				/* Card Detect (CD), active low (pull-up) */
				MX6QDL_PAD_GPIO_1__GPIO1_IO01		0x17000
			>;
		};

		pinctrl_usdhc1_100mhz: usdhc1grp100mhz {
			fsl,pins = <
				MX6QDL_PAD_SD1_CMD__SD1_CMD		0x170b9
				MX6QDL_PAD_SD1_CLK__SD1_CLK		0x100b9
				MX6QDL_PAD_SD1_DAT0__SD1_DATA0		0x170b9
				MX6QDL_PAD_SD1_DAT1__SD1_DATA1		0x170b9
				MX6QDL_PAD_SD1_DAT2__SD1_DATA2		0x170b9
				MX6QDL_PAD_SD1_DAT3__SD1_DATA3		0x170b9
				/* WLAN_RESET with external pull-down */
				MX6QDL_PAD_ENET_RXD1__GPIO1_IO26	0x100b0
				/* Card Detect (CD), active low (pull-up) */
				MX6QDL_PAD_GPIO_1__GPIO1_IO01		0x17000
			>;
		};

		pinctrl_usdhc1_200mhz: usdhc1grp200mhz {
			fsl,pins = <
				MX6QDL_PAD_SD1_CMD__SD1_CMD		0x170f9
				MX6QDL_PAD_SD1_CLK__SD1_CLK		0x100f9
				MX6QDL_PAD_SD1_DAT0__SD1_DATA0		0x170f9
				MX6QDL_PAD_SD1_DAT1__SD1_DATA1		0x170f9
				MX6QDL_PAD_SD1_DAT2__SD1_DATA2		0x170f9
				MX6QDL_PAD_SD1_DAT3__SD1_DATA3		0x170f9
				/* WLAN_RESET with external pull-down */
				MX6QDL_PAD_ENET_RXD1__GPIO1_IO26	0x100b0
				/* Card Detect (CD), active low (pull-up) */
				MX6QDL_PAD_GPIO_1__GPIO1_IO01		0x17000
			>;
		};
#endif

#ifdef CONFIG_QBLISSA9R2_SD_A
		pinctrl_usdhc2: usdhc2grp {
			fsl,pins = <
				MX6QDL_PAD_SD2_CMD__SD2_CMD		0x170b1
				MX6QDL_PAD_SD2_CLK__SD2_CLK		0x100b1
				MX6QDL_PAD_SD2_DAT0__SD2_DATA0		0x170b1
				MX6QDL_PAD_SD2_DAT1__SD2_DATA1		0x170b1
				MX6QDL_PAD_SD2_DAT2__SD2_DATA2		0x170b1
				MX6QDL_PAD_SD2_DAT3__SD2_DATA3		0x170b1
				/* SD_A power, active low */
				MX6QDL_PAD_EIM_DA14__GPIO3_IO14		0x170b0
#ifdef CONFIG_QBLISSA9R2_SD_A_CD
				/* Card Detect (CD), active low (pull-up) */
				MX6QDL_PAD_GPIO_4__GPIO1_IO04		0x17000
#endif
#ifdef CONFIG_QBLISSA9R2_SD_A_WP
				/*
				 * Write Protect (WP), active high (pull-up)
				 * lock:   WP switch open, pulled high
				 * unlock: WP switch closed, connects to GND
				 */
				MX6QDL_PAD_GPIO_2__GPIO1_IO02		0x17000
#endif
			>;
		};
#endif

#ifdef CONFIG_QBLISSA9R2_EMMC
		pinctrl_usdhc3: usdhc3grp {
			fsl,pins = <
				MX6QDL_PAD_SD3_CMD__SD3_CMD		0x17091
				MX6QDL_PAD_SD3_CLK__SD3_CLK		0x10091
				MX6QDL_PAD_SD3_DAT0__SD3_DATA0		0x17091
				MX6QDL_PAD_SD3_DAT1__SD3_DATA1		0x17091
				MX6QDL_PAD_SD3_DAT2__SD3_DATA2		0x17091
				MX6QDL_PAD_SD3_DAT3__SD3_DATA3		0x17091
				MX6QDL_PAD_SD3_DAT4__SD3_DATA4		0x17091
				MX6QDL_PAD_SD3_DAT5__SD3_DATA5		0x17091
				MX6QDL_PAD_SD3_DAT6__SD3_DATA6		0x17091
				MX6QDL_PAD_SD3_DAT7__SD3_DATA7		0x17091
				/* Reset eMMC, active low */
				MX6QDL_PAD_SD3_RST__SD3_RESET		0x17091
			>;
		};
#endif

		/* Internal I2C, always active */
		pinctrl_i2c1: i2c1grp {
			fsl,pins = <
				MX6QDL_PAD_CSI0_DAT8__I2C1_SDA		0x4001b8b1
				MX6QDL_PAD_CSI0_DAT9__I2C1_SCL		0x4001b8b1
			>;
		};

#ifdef CONFIG_QBLISSA9R2_I2C_A
		pinctrl_i2c3: i2c3grp-1 {
			fsl,pins = <
				MX6QDL_PAD_GPIO_3__I2C3_SCL		0x4001b8b1
				MX6QDL_PAD_GPIO_16__I2C3_SDA		0x4001b8b1
			>;
		};
#endif

#ifdef CONFIG_QBLISSA9R2_I2C_B
		pinctrl_i2c2: i2c2grp {
			fsl,pins = <
				MX6QDL_PAD_KEY_COL3__I2C2_SCL		0x4001b8b1
				MX6QDL_PAD_KEY_ROW3__I2C2_SDA		0x4001b8b1
				/* IRQ */
				MX6QDL_PAD_ENET_TXD0__GPIO1_IO30	0x17000
			>;
		};
#endif

#ifdef CONFIG_QBLISSA9R2_I2C_C
		pinctrl_i2c_gpio_c: i2c_gpio_c_grp {
			fsl,pins = <
				MX6QDL_PAD_SD4_DAT6__GPIO2_IO14		0x070b1
				MX6QDL_PAD_SD4_DAT7__GPIO2_IO15		0x070b1
			>;
		};
#endif

#ifdef CONFIG_QBLISSA9R2_I2C_D
		pinctrl_i2c_gpio_d: i2c_gpio_d_grp {
			fsl,pins = <
				MX6QDL_PAD_DISP0_DAT14__GPIO5_IO08	0x070b1
				MX6QDL_PAD_DISP0_DAT15__GPIO5_IO09	0x070b1
			>;
		};
#endif

#ifdef CONFIG_QBLISSA9R2_HDMI
		pinctrl_i2c_gpio_hdmi: i2c6_gpio_hdmi_grp {
			fsl,pins = <
				MX6QDL_PAD_DISP0_DAT16__GPIO5_IO10	0x03039
				MX6QDL_PAD_DISP0_DAT17__GPIO5_IO11	0x03039
			>;
		};
#endif

#ifdef CONFIG_QBLISSA9R2_SERIAL_CAMERA
		pinctrl_i2c_gpio_cam1: i2c_gpio_cam1_grp {
			fsl,pins = <
				MX6QDL_PAD_CSI0_DAT14__GPIO6_IO00	0x07048
				MX6QDL_PAD_CSI0_DAT15__GPIO6_IO01	0x07048
			>;
		};
#endif

#ifdef CONFIG_QBLISSA9R2_PWM_A
		pinctrl_pwm3: pwm3grp {
			fsl,pins = <
				MX6QDL_PAD_SD4_DAT1__PWM3_OUT		0x110b0
			>;
		};
#endif

#ifdef CONFIG_QBLISSA9R2_PWM_B
		pinctrl_pwm4: pwm4grp {
			fsl,pins = <
				MX6QDL_PAD_SD4_DAT2__PWM4_OUT		0x110b0
			>;
		};
#endif

#ifdef CONFIG_QBLISSA9R2_PWM_C
		pinctrl_pwm1: pwm1grp {
			fsl,pins = <
				MX6QDL_PAD_DISP0_DAT8__PWM1_OUT		0x110b0
			>;
		};
#endif

#ifdef CONFIG_QBLISSA9R2_PCIE
		pinctrl_pcie: pciegrp {
			fsl,pins = <
				/* PCIE_WAKE */
				MX6QDL_PAD_NANDF_CS3__GPIO6_IO16	0x1b0b0
				/* PCIE_RST: see above in Hog */
			>;
		};
#endif /* CONFIG_QBLISSA9R2_PCIE */

#ifdef CONFIG_QBLISSA9R2_HDMI_CEC
		pinctrl_hdmi_cec_1: hdmicecgrp {
			fsl,pins = <
				MX6QDL_PAD_EIM_A25__HDMI_TX_CEC_LINE	0x1f8b0
			>;
		};
#endif /* CONFIG_QBLISSA9R2_HDMI_CEC */

		pinctrl_status_leds: ledgrp {
			fsl,pins = <
				MX6QDL_PAD_GPIO_17__GPIO7_IO12		0x80000000
				MX6QDL_PAD_GPIO_18__GPIO7_IO13		0x80000000
			>;
		};
	};
};
